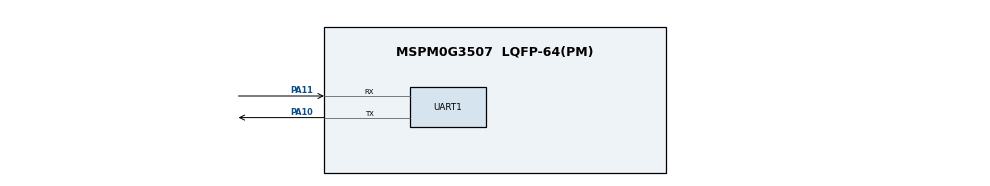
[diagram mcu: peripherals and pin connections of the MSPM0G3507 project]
//@cliArgs --device "MSPM0G350X" --package "LQFP-64(PM)" --part "Default"
//@v2CliArgs --device "MSPM0G3507" --package "LQFP-64(PM)"
// @cliArgs --board /ti/boards/LP_MSPM0G3507 --rtos nortos

/**
 * Import the modules used in this configuration.
 */
const ProjectConfig = scripting.addModule("/ti/project_config/ProjectConfig");
const GPIO          = scripting.addModule("/ti/driverlib/GPIO", {}, false);
const GPIO1         = GPIO.addInstance();
const GPIO2         = GPIO.addInstance();
const SYSCTL        = scripting.addModule("/ti/driverlib/SYSCTL");
const TIMER         = scripting.addModule("/ti/driverlib/TIMER", {}, false);
const TIMER1        = TIMER.addInstance();
const UART          = scripting.addModule("/ti/driverlib/UART", {}, false);
const UART1         = UART.addInstance();

/**
 * Write custom configuration values to the imported modules.
 */
ProjectConfig.genDisable                 = true;

GPIO1.$name                              = "GPIO_SWITCHES_1";
GPIO1.port                               = "PORTB";
GPIO1.associatedPins.create(1);
GPIO1.associatedPins[0].$name            = "USER_SWITCH_1";
GPIO1.associatedPins[0].assignedPin      = "21";
GPIO1.associatedPins[0].direction        = "INPUT";
GPIO1.associatedPins[0].internalResistor = "PULL_UP";
GPIO1.associatedPins[0].polarity         = "FALL";
GPIO1.associatedPins[0].interruptEn      = true;
GPIO2.$name                              = "GPIO_SWITCHES_2";
GPIO2.port                               = "PORTA";
GPIO2.associatedPins.create(1);
GPIO2.associatedPins[0].$name            = "USER_SWITCH_2";
GPIO2.associatedPins[0].assignedPin      = "18";
GPIO2.associatedPins[0].direction        = "INPUT";
GPIO2.associatedPins[0].polarity         = "RISE";
GPIO2.associatedPins[0].interruptEn      = true;

const Board = scripting.addModule("/ti/driverlib/Board", {}, false);

TIMER1.timerMode          = "PERIODIC";
TIMER1.timerPeriod        = "500 ms";
TIMER1.timerClkPrescale   = 256;
TIMER1.interrupts         = ["ZERO"];
TIMER1.$name              = "TIMER";
TIMER1.peripheral.$assign = "TIMG0";

UART1.enabledInterrupts        = ["RX"];
UART1.$name                    = "UART";
UART1.peripheral.$assign       = "UART0";
UART1.peripheral.rxPin.$assign = "PA11";
UART1.peripheral.txPin.$assign = "PA10";
